# nrf7120E_enga_application register map
Vendor: Nordic Semiconductor; Series: nrf71; File version: 1
CPU: CM33 r0p4, little endian, MPU, FPU, 3 interrupt priority bits, 270 interrupts, 4 SAU regions
Registers are 32-bit, read-write, reset 0x0 unless marked. A register's access mark holds for its fields unless they carry their own. Offsets are from the block's base; [hi:lo] are bit positions; lines under a group give offsets from that group; {n}, {i} and the like mark numbered series.

## GLOBAL_FICR_NS — Factory Information Configuration Registers
Base 0x00FFC000
0x300 INFO group — Device info
  0x00 CONFIGID rw-once reset 0xFFFFFFFF — Configuration identifier
    [15:0] HWID — Identification number for the HW
  {0x4+4j} DEVICEID[{j}] (j=0..1) rw-once reset 0xFFFFFFFF — Description collection: Device identifier
    [31:0] DEVICEID — 64 bit unique device identifier
  {0xC+4j} UUID[{j}] (j=0..3) rw-once reset 0xFFFFFFFF — Description collection: 128-bit Universally Unique IDentifier (UUID).
    [31:0] UUID — Device UUID [n].
  0x1C PART rw-once reset 0xFFFFFFFF — Part code
    [31:0] PART
      0x71200=N7120 (nRF7120); 0x7120E=N7120E (nRF7120E); 0xFFFFFFFF=Unspecified
  0x20 VARIANT rw-once reset 0xFFFFFFFF — Function variant code, Hardware version code, and Production configuration code encoded as ASCII.
    [31:0] VARIANT — Function variant code, Hardware version code, and Production configuration code encoded as ASCII
      0x41414230=AAB0 (Example encoding for AAB0 - Function variant code AA, Hardware version code B, Production configuration code 0); 0xFFFFFFFF=Unspecified
  0x24 PACKAGE rw-once reset 0xFFFFFFFF — Package option
    [31:0] PACKAGE
      0xFFFFFFFF=Unspecified
  0x28 RAM rw-once reset 0xFFFFFFFF — RAM size (KB)
    [31:0] RAM
      0x3F8=K1016 (1016 kByte RAM); 0xFFFFFFFF=Unspecified
  0x30 MRAM rw-once reset 0xFFFFFFFF — MRAM size (KB)
    [31:0] MRAM
      0xFEC=K4076 (4076 KByte MRAM); 0xFFFFFFFF=Unspecified
  0x3C NORDICID rw-once — Nordic Identity supported indicator
    [31:0] SUPPORT
      1=Supported (This device does support Nordic Identity); 0xFFFFFFFF=NotSupported (This device does not support Nordic Identity)
0x340 SOCINFO group — Unspecified
  0x04 HWREVISION rw-once reset 0xFFFFFFFF — Hardware Revision of the device. Will be updated in production test.
    [31:0] HWREVISION
      0=SOC1 (Unspecified)
{0x380+4i} ER[{i}] (i=0..3) rw-once reset 0xFFFFFFFF — Description collection: Common encryption root key, word n
  [31:0] ER — Encryption Root, word n
{0x390+4i} IR[{i}] (i=0..3) rw-once reset 0xFFFFFFFF — Description collection: Common identity root key, word n
  [31:0] IR — Identity Root, word n
0x3A0 DEVICEADDRTYPE rw-once reset 0xFFFFFFFF — Device address type
  [0] DEVICEADDRTYPE
    0=Public address; 1=Random address
{0x3A4+4i} DEVICEADDR[{i}] (i=0..1) rw-once reset 0xFFFFFFFF — Description collection: Device address n
  [31:0] DEVICEADDR — 48 bit device address
{0x400+8i} TRIMCNF[{i}] (i=0..127) group — Unspecified
  0x00 ADDR rw-once reset 0xFFFFFFFF — Description cluster: Address of the register which will be written
    [31:0] Address
  0x04 DATA rw-once reset 0xFFFFFFFF — Description cluster: Data to be written into the register
0x900 NFC group — Unspecified
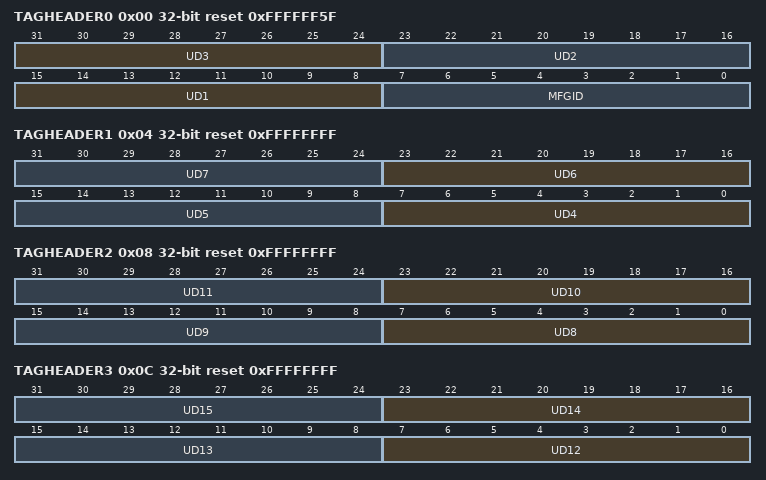
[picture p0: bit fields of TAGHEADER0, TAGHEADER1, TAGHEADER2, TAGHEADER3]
  0x00 TAGHEADER0 rw-once reset 0xFFFFFF5F — Default header for NFC Tag. Software can read these values to populate NFCID1_3RD_LAST, NFCID1_2ND_LAST and NFCID1_LAST.
    [31:24] UD3 — Unique identifier byte 3
    [23:16] UD2 — Unique identifier byte 2
    [15:8] UD1 — Unique identifier byte 1
    [7:0] MFGID — Default Manufacturer ID: Nordic Semiconductor ASA has ICM 0x5F
  0x04 TAGHEADER1 rw-once reset 0xFFFFFFFF — Default header for NFC Tag. Software can read these values to populate NFCID1_3RD_LAST, NFCID1_2ND_LAST and NFCID1_LAST.
    [8n-25:8n-32] UD{n} (n=4..7) — Unique identifier byte {n}
  0x08 TAGHEADER2 rw-once reset 0xFFFFFFFF — Default header for NFC Tag. Software can read these values to populate NFCID1_3RD_LAST, NFCID1_2ND_LAST and NFCID1_LAST.
    [8n-57:8n-64] UD{n} (n=8..11) — Unique identifier byte {n}
  0x0C TAGHEADER3 rw-once reset 0xFFFFFFFF — Default header for NFC Tag. Software can read these values to populate NFCID1_3RD_LAST, NFCID1_2ND_LAST and NFCID1_LAST.
    [8n-89:8n-96] UD{n} (n=12..15) — Unique identifier byte {n}
0x980 LFRC32KTRIM group — Unspecified
  0x00 LFRCOSCTRIM rw-once reset 0x2C — Initial coarse frequency trimming value for the oscillator.
    [5:0] VAL — TRIM value
0x990 AUXPLL group — Unspecified
  0x00 AUDIOCTUNE rw-once reset 0xFFFFFFFF — AUXPLL audio CTUNE value written by production test.
    [31:0] DATA — Trim data
  0x04 USBCTUNE rw-once reset 0xFFFFFFFF — AUXPLL USB CTUNE value written by production test.
    [31:0] DATA — Trim data
{0xC00+8i} MACADDR[{i}] (i=0..1) group — 48-bit MAC address n
  0x00 LOW rw-once reset 0xFFFFFFFF — Description cluster: Lower 24 bits of MAC address n
    [23:0] ADDR — MAC address bits [23:0]
  0x04 HIGH rw-once reset 0xFFFFFFFF — Description cluster: Upper 24 bits of MAC address n
    [23:0] ADDR — MAC address bits [47:24]
0xC20 XTALCOMP group — Crystal oscillator (XTAL) temperature compensation data
  0x00 OFFSET rw-once reset 0xFFFFFFFF — Measured XTAL frequency error at room temperature
    [31:0] OFFSET — Frequency error in ppm
  0x04 LOWTEMPTHRESHOLD rw-once reset 0xFFFFFFFF — Low temperature threshold for frequency skew compensation
    [31:0] THRESHOLD — Low temperature threshold
  0x08 LOWTEMPADJUST rw-once reset 0xFFFFFFFF — Frequency adjustment applied below the low temperature threshold
    [31:0] ADJUST — Frequency adjustment in ppm

## Notices in the file
Copyright (c) 2010 - 2026, Nordic Semiconductor ASA All rights reserved.
SPDX-License-Identifier: BSD-3-Clause
Redistribution and use in source and binary forms, with or without
modification, are permitted provided that the following conditions are met:
1. Redistributions of source code must retain the above copyright notice, this
list of conditions and the following disclaimer.
2. Redistributions in binary form must reproduce the above copyright
notice, this list of conditions and the following disclaimer in the
documentation and/or other materials provided with the distribution.
3. Neither the name of Nordic Semiconductor ASA nor the names of its
contributors may be used to endorse or promote products derived from this
software without specific prior written permission.
THIS SOFTWARE IS PROVIDED BY THE COPYRIGHT HOLDERS AND CONTRIBUTORS "AS IS"
AND ANY EXPRESS OR IMPLIED WARRANTIES, INCLUDING, BUT NOT LIMITED TO, THE
IMPLIED WARRANTIES OF MERCHANTABILITY, AND FITNESS FOR A PARTICULAR PURPOSE
ARE DISCLAIMED. IN NO EVENT SHALL NORDIC SEMICONDUCTOR ASA OR CONTRIBUTORS BE
LIABLE FOR ANY DIRECT, INDIRECT, INCIDENTAL, SPECIAL, EXEMPLARY, OR
CONSEQUENTIAL DAMAGES (INCLUDING, BUT NOT LIMITED TO, PROCUREMENT OF
SUBSTITUTE GOODS OR SERVICES; LOSS OF USE, DATA, OR PROFITS; OR BUSINESS
INTERRUPTION) HOWEVER CAUSED AND ON ANY THEORY OF LIABILITY, WHETHER IN
CONTRACT, STRICT LIABILITY, OR TORT (INCLUDING NEGLIGENCE OR OTHERWISE)
ARISING IN ANY WAY OUT OF THE USE OF THIS SOFTWARE, EVEN IF ADVISED OF THE
POSSIBILITY OF SUCH DAMAGE.
